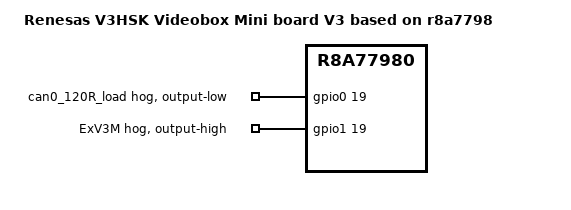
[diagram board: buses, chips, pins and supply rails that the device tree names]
/*
 * Device Tree Source for the V3MSK Videobox Mini board V3 on r8a7797
 *
 * Copyright (C) 2018 Cogent Embedded, Inc.
 *
 * This file is licensed under the terms of the GNU General Public License
 * version 2.  This program is licensed "as is" without any warranty of any
 * kind, whether express or implied.
 */

#include "r8a77980-v3hsk-vbm-v2.dts"


/ {
	model = "Renesas V3HSK Videobox Mini board V3 based on r8a7798";
};

&gpio0 {
	can0_load {
		gpio-hog;
		gpios = <19 GPIO_ACTIVE_HIGH>;
		output-low;
		line-name = "can0_120R_load";
	};
};

&gpio1 {
	ex_v3m {
		gpio-hog;
		gpios = <19 GPIO_ACTIVE_HIGH>;
		output-high;
		line-name = "ExV3M";
	};
};

&gpio2 {
	/delete-node/can0_load;
};
